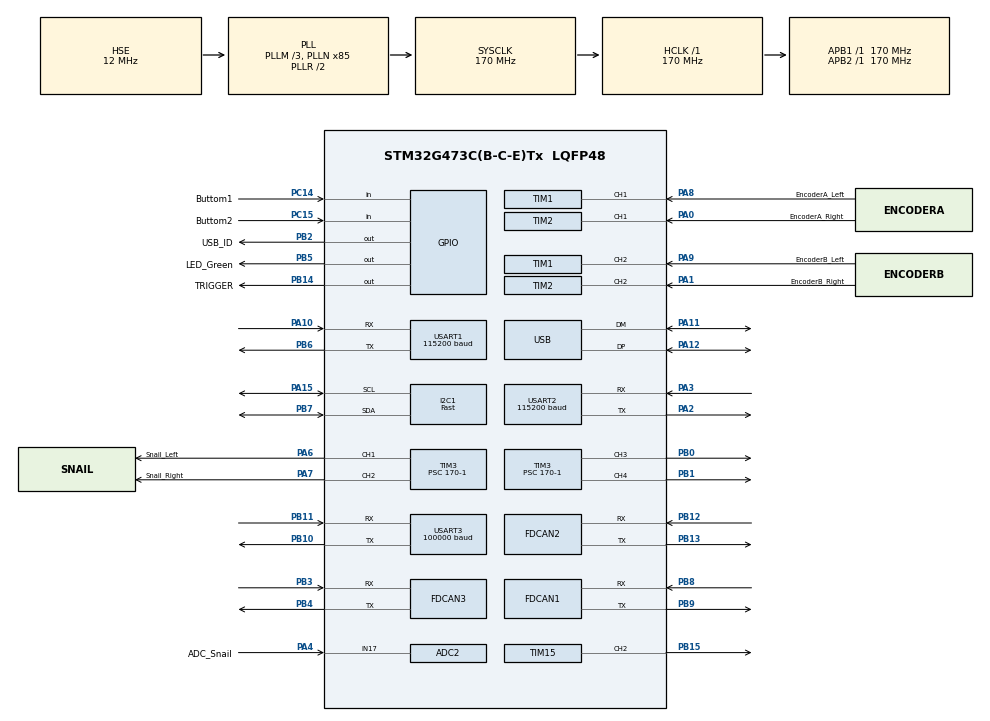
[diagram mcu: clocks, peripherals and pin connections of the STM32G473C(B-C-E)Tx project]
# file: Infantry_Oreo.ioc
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ADC2.Channel-2\#ChannelRegularConversion=ADC_CHANNEL_17
ADC2.ContinuousConvMode=ENABLE
ADC2.DMAContinuousRequests=ENABLE
ADC2.EOCSelection=ADC_EOC_SEQ_CONV
ADC2.NbrOfConversion=1
ADC2.NbrOfConversionFlag=1
ADC2.OffsetNumber-2\#ChannelRegularConversion=ADC_OFFSET_NONE
ADC2.OversamplingMode=ENABLE
ADC2.Rank-2\#ChannelRegularConversion=1
ADC2.Ratio=ADC_OVERSAMPLING_RATIO_256
ADC2.RightBitShift=ADC_RIGHTBITSHIFT_4
ADC2.SamplingTime-2\#ChannelRegularConversion=ADC_SAMPLETIME_6CYCLES_5
Dma.ADC2.3.Direction=DMA_PERIPH_TO_MEMORY
Dma.ADC2.3.EventEnable=DISABLE
Dma.ADC2.3.Instance=DMA1_Channel2
Dma.ADC2.3.MemDataAlignment=DMA_MDATAALIGN_WORD
Dma.ADC2.3.MemInc=DMA_MINC_ENABLE
Dma.ADC2.3.Mode=DMA_CIRCULAR
Dma.ADC2.3.PeriphDataAlignment=DMA_PDATAALIGN_WORD
Dma.ADC2.3.PeriphInc=DMA_PINC_DISABLE
Dma.ADC2.3.Polarity=HAL_DMAMUX_REQ_GEN_RISING
Dma.ADC2.3.Priority=DMA_PRIORITY_LOW
Dma.ADC2.3.RequestNumber=1
Dma.ADC2.3.SignalID=NONE
Dma.ADC2.3.SyncEnable=DISABLE
Dma.ADC2.3.SyncPolarity=HAL_DMAMUX_SYNC_NO_EVENT
Dma.ADC2.3.SyncRequestNumber=1
Dma.ADC2.3.SyncSignalID=NONE
Dma.Request0=USART2_RX
Dma.Request1=USART1_RX
Dma.Request2=USART3_RX
Dma.Request3=ADC2
Dma.USART1_RX.1.Direction=DMA_PERIPH_TO_MEMORY
Dma.USART1_RX.1.EventEnable=DISABLE
Dma.USART1_RX.1.Instance=DMA1_Channel4
Dma.USART1_RX.1.MemDataAlignment=DMA_MDATAALIGN_BYTE
Dma.USART1_RX.1.MemInc=DMA_MINC_ENABLE
Dma.USART1_RX.1.Mode=DMA_CIRCULAR
Dma.USART1_RX.1.PeriphDataAlignment=DMA_PDATAALIGN_BYTE
Dma.USART1_RX.1.PeriphInc=DMA_PINC_DISABLE
Dma.USART1_RX.1.Polarity=HAL_DMAMUX_REQ_GEN_RISING
Dma.USART1_RX.1.Priority=DMA_PRIORITY_LOW
Dma.USART1_RX.1.RequestNumber=1
Dma.USART1_RX.1.SignalID=NONE
Dma.USART1_RX.1.SyncEnable=DISABLE
Dma.USART1_RX.1.SyncPolarity=HAL_DMAMUX_SYNC_NO_EVENT
Dma.USART1_RX.1.SyncRequestNumber=1
Dma.USART1_RX.1.SyncSignalID=NONE
Dma.USART2_RX.0.Direction=DMA_PERIPH_TO_MEMORY
Dma.USART2_RX.0.EventEnable=DISABLE
Dma.USART2_RX.0.Instance=DMA1_Channel3
Dma.USART2_RX.0.MemDataAlignment=DMA_MDATAALIGN_BYTE
Dma.USART2_RX.0.MemInc=DMA_MINC_ENABLE
Dma.USART2_RX.0.Mode=DMA_CIRCULAR
Dma.USART2_RX.0.PeriphDataAlignment=DMA_PDATAALIGN_BYTE
Dma.USART2_RX.0.PeriphInc=DMA_PINC_DISABLE
Dma.USART2_RX.0.Polarity=HAL_DMAMUX_REQ_GEN_RISING
Dma.USART2_RX.0.Priority=DMA_PRIORITY_LOW
Dma.USART2_RX.0.RequestNumber=1
Dma.USART2_RX.0.SignalID=NONE
Dma.USART2_RX.0.SyncEnable=DISABLE
Dma.USART2_RX.0.SyncPolarity=HAL_DMAMUX_SYNC_NO_EVENT
Dma.USART2_RX.0.SyncRequestNumber=1
Dma.USART2_RX.0.SyncSignalID=NONE
Dma.USART3_RX.2.Direction=DMA_PERIPH_TO_MEMORY
Dma.USART3_RX.2.EventEnable=DISABLE
Dma.USART3_RX.2.Instance=DMA1_Channel1
Dma.USART3_RX.2.MemDataAlignment=DMA_MDATAALIGN_BYTE
Dma.USART3_RX.2.MemInc=DMA_MINC_ENABLE
Dma.USART3_RX.2.Mode=DMA_CIRCULAR
Dma.USART3_RX.2.PeriphDataAlignment=DMA_PDATAALIGN_BYTE
Dma.USART3_RX.2.PeriphInc=DMA_PINC_DISABLE
Dma.USART3_RX.2.Polarity=HAL_DMAMUX_REQ_GEN_RISING
Dma.USART3_RX.2.Priority=DMA_PRIORITY_LOW
Dma.USART3_RX.2.RequestNumber=1
Dma.USART3_RX.2.SignalID=NONE
Dma.USART3_RX.2.SyncEnable=DISABLE
Dma.USART3_RX.2.SyncPolarity=HAL_DMAMUX_SYNC_NO_EVENT
Dma.USART3_RX.2.SyncRequestNumber=1
Dma.USART3_RX.2.SyncSignalID=NONE
FDCAN1.AutoRetransmission=DISABLE
FDCAN1.DataPrescaler=2
FDCAN1.DataTimeSeg1=10
FDCAN1.DataTimeSeg2=6
FDCAN1.ExtFiltersNbr=8
FDCAN1.FrameFormat=FDCAN_FRAME_FD_BRS
FDCAN1.Mode=FDCAN_MODE_NORMAL
FDCAN1.NominalPrescaler=17
FDCAN1.NominalTimeSeg1=6
FDCAN1.NominalTimeSeg2=3
FDCAN1.ProtocolException=DISABLE
FDCAN1.StdFiltersNbr=8
FDCAN1.TransmitPause=DISABLE
FDCAN2.AutoRetransmission=DISABLE
FDCAN2.DataPrescaler=2
FDCAN2.DataTimeSeg1=10
FDCAN2.DataTimeSeg2=6
FDCAN2.ExtFiltersNbr=8
FDCAN2.FrameFormat=FDCAN_FRAME_FD_BRS
FDCAN2.Mode=FDCAN_MODE_NORMAL
FDCAN2.NominalPrescaler=17
FDCAN2.NominalTimeSeg1=6
FDCAN2.NominalTimeSeg2=3
FDCAN2.ProtocolException=DISABLE
FDCAN2.StdFiltersNbr=8
FDCAN2.TransmitPause=DISABLE
FDCAN3.AutoRetransmission=DISABLE
FDCAN3.DataPrescaler=2
FDCAN3.DataTimeSeg1=10
FDCAN3.DataTimeSeg2=6
FDCAN3.ExtFiltersNbr=8
FDCAN3.FrameFormat=FDCAN_FRAME_FD_BRS
FDCAN3.Mode=FDCAN_MODE_NORMAL
FDCAN3.NominalPrescaler=17
FDCAN3.NominalTimeSeg1=6
FDCAN3.NominalTimeSeg2=3
FDCAN3.ProtocolException=DISABLE
FDCAN3.StdFiltersNbr=8
FDCAN3.TransmitPause=DISABLE
FREERTOS.INCLUDE_eTaskGetState=1
FREERTOS.INCLUDE_pcTaskGetTaskName=1
FREERTOS.INCLUDE_uxTaskGetStackHighWaterMark=1
FREERTOS.INCLUDE_uxTaskGetStackHighWaterMark2=1
FREERTOS.INCLUDE_vTaskCleanUpResources=1
FREERTOS.INCLUDE_vTaskDelayUntil=1
FREERTOS.INCLUDE_xQueueGetMutexHolder=1
FREERTOS.INCLUDE_xSemaphoreGetMutexHolder=1
FREERTOS.INCLUDE_xTaskAbortDelay=1
FREERTOS.INCLUDE_xTaskGetCurrentTaskHandle=1
FREERTOS.INCLUDE_xTaskGetHandle=1
FREERTOS.MEMORY_ALLOCATION=2
FREERTOS.Queues01=Key_Queue,16,uint16_t,0,Dynamic,NULL,NULL
FREERTOS.Tasks01=defaultTask,0,128,StartDefaultTask,As weak,NULL,Dynamic,NULL,NULL;Gimbal,2,128,Gimbal_Task,As weak,NULL,Dynamic,NULL,NULL;BusComm,3,128,BusComm_Task,As weak,NULL,Dynamic,NULL,NULL;Chassis,2,128,Chassis_Task,As weak,NULL,Dynamic,NULL,NULL;Shoot,2,128,Shoot_Task,As weak,NULL,Dynamic,NULL,NULL;MiniPC,0,128,MiniPC_Task,As weak,NULL,Dynamic,NULL,NULL;Referee,2,128,Referee_Task,As weak,NULL,Dynamic,NULL,NULL;WatchDog,0,128,WatchDog_Task,As weak,NULL,Dynamic,NULL,NULL;Client,0,128,Client_Task,As weak,NULL,Dynamic,NULL,NULL;Ins,0,128,Ins_Task,As weak,NULL,Dynamic,NULL,NULL;Init,3,128,Init_Task,As weak,NULL,Dynamic,NULL,NULL;SuperCap,2,128,SuperCap_Task,As weak,NULL,Dynamic,NULL,NULL
FREERTOS.configENABLE_FPU=1
FREERTOS.configTOTAL_HEAP_SIZE=15360
I2C1.I2C_Speed_Mode=I2C_Fast
I2C1.Timing=0x10802D9B
Mcu.Family=STM32G4
Mcu.Name=STM32G473C(B-C-E)Tx
Mcu.Package=LQFP48
NVIC.ADC1_2_IRQn=true\:5\:0\:false\:false\:true\:true\:true\:true\:true
NVIC.DMA1_Channel1_IRQn=true\:5\:0\:false\:false\:true\:true\:false\:true\:true
NVIC.DMA1_Channel2_IRQn=true\:5\:0\:false\:false\:true\:true\:false\:true\:true
NVIC.DMA1_Channel3_IRQn=true\:5\:0\:false\:false\:true\:true\:false\:true\:true
NVIC.DMA1_Channel4_IRQn=true\:5\:0\:false\:false\:true\:true\:false\:true\:true
NVIC.FDCAN1_IT0_IRQn=true\:5\:0\:false\:false\:true\:true\:true\:true\:true
NVIC.FDCAN2_IT0_IRQn=true\:5\:0\:false\:false\:true\:true\:true\:true\:true
NVIC.FDCAN3_IT0_IRQn=true\:5\:0\:false\:false\:true\:true\:true\:true\:true
NVIC.PriorityGroup=NVIC_PRIORITYGROUP_4
NVIC.TIM20_UP_IRQn=true\:15\:0\:false\:false\:true\:false\:false\:true\:true
NVIC.TimeBase=TIM20_UP_IRQn
NVIC.TimeBaseIP=TIM20
NVIC.USART1_IRQn=true\:5\:0\:false\:false\:true\:true\:true\:true\:true
NVIC.USART2_IRQn=true\:5\:0\:false\:false\:true\:true\:true\:true\:true
NVIC.USART3_IRQn=true\:5\:0\:false\:false\:true\:true\:true\:true\:true
NVIC.USB_LP_IRQn=true\:5\:0\:false\:false\:true\:true\:false\:true\:true
PA0.GPIO_Label=EncoderA_Right
PA0.Signal=S_TIM2_CH1
PA1.GPIO_Label=EncoderB_Right
PA1.Signal=S_TIM2_CH2
PA10.Mode=Asynchronous
PA10.Signal=USART1_RX
PA11.Mode=Device
PA11.Signal=USB_DM
PA12.Mode=Device
PA12.Signal=USB_DP
PA13.Mode=Serial_Wire
PA13.Signal=SYS_JTMS-SWDIO
PA14.Mode=Serial_Wire
PA14.Signal=SYS_JTCK-SWCLK
PA15.Mode=I2C
PA15.Signal=I2C1_SCL
PA2.Mode=Asynchronous
PA2.Signal=USART2_TX
PA3.Mode=Asynchronous
PA3.Signal=USART2_RX
PA4.GPIO_Label=ADC_Snail
PA4.Mode=IN17-Single-Ended
PA4.Signal=ADC2_IN17
PA6.GPIO_Label=Snail_Left
PA6.Signal=S_TIM3_CH1
PA7.GPIO_Label=Snail_Right
PA7.Signal=S_TIM3_CH2
PA8.GPIO_Label=EncoderA_Left
PA8.Signal=S_TIM1_CH1
PA9.GPIO_Label=EncoderB_Left
PA9.Signal=S_TIM1_CH2
PB0.Signal=S_TIM3_CH3
PB1.Signal=S_TIM3_CH4
PB10.Mode=Asynchronous
PB10.Signal=USART3_TX
PB11.Mode=Asynchronous
PB11.Signal=USART3_RX
PB12.Mode=FDCAN_Activate
PB12.Signal=FDCAN2_RX
PB13.Mode=FDCAN_Activate
PB13.Signal=FDCAN2_TX
PB14.GPIO_Label=TRIGGER
PB14.GPIO_Speed=GPIO_SPEED_FREQ_MEDIUM
PB14.Signal=GPIO_Output
PB15.Signal=S_TIM15_CH2
PB2.GPIO_Label=USB_ID
PB2.Signal=GPIO_Output
PB3.Mode=FDCAN_Activate
PB3.Signal=FDCAN3_RX
PB4.Mode=FDCAN_Activate
PB4.Signal=FDCAN3_TX
PB5.GPIO_Label=LED_Green
PB5.Signal=GPIO_Output
PB6.Mode=Asynchronous
PB6.Signal=USART1_TX
PB7.Mode=I2C
PB7.Signal=I2C1_SDA
PB8-BOOT0.Mode=FDCAN_Activate
PB8-BOOT0.Signal=FDCAN1_RX
PB9.Mode=FDCAN_Activate
PB9.Signal=FDCAN1_TX
PC14-OSC32_IN.GPIO_Label=Buttom1
PC14-OSC32_IN.Signal=GPIO_Input
PC15-OSC32_OUT.GPIO_Label=Buttom2
PC15-OSC32_OUT.Signal=GPIO_Input
PF0-OSC_IN.Mode=HSE-External-Oscillator
PF0-OSC_IN.Signal=RCC_OSC_IN
PF1-OSC_OUT.Mode=HSE-External-Oscillator
PF1-OSC_OUT.Signal=RCC_OSC_OUT
ProjectManager.HeapSize=0x1000
ProjectManager.StackSize=0x8000
ProjectManager.TargetToolchain=MDK-ARM V5.32
RCC.ADC12Freq_Value=170000000
RCC.ADC345Freq_Value=170000000
RCC.AHBFreq_Value=170000000
RCC.APB1Freq_Value=170000000
RCC.APB1TimFreq_Value=170000000
RCC.APB2Freq_Value=170000000
RCC.APB2TimFreq_Value=170000000
RCC.CK48CLockSelection=RCC_USBCLKSOURCE_HSI48
RCC.CortexFreq_Value=170000000
RCC.EXTERNAL_CLOCK_VALUE=12288000
RCC.HCLKFreq_Value=170000000
RCC.HSE_VALUE=12000000
RCC.HSI48_VALUE=48000000
RCC.HSI_VALUE=16000000
RCC.LSE_VALUE=32768
RCC.PLLM=RCC_PLLM_DIV3
RCC.PLLN=85
RCC.PLLQ=RCC_PLLQ_DIV4
RCC.PLLSourceVirtual=RCC_PLLSOURCE_HSE
RCC.SYSCLKFreq_VALUE=170000000
RCC.SYSCLKSource=RCC_SYSCLKSOURCE_PLLCLK
RCC.USBFreq_Value=48000000
RCC.VCOOutputFreq_Value=340000000
SH.S_TIM15_CH2.0=TIM15_CH2,PWM Generation2 CH2
SH.S_TIM1_CH1.0=TIM1_CH1,Encoder_Interface
SH.S_TIM1_CH2.0=TIM1_CH2,Encoder_Interface
SH.S_TIM2_CH1.0=TIM2_CH1,Encoder_Interface
SH.S_TIM2_CH2.0=TIM2_CH2,Encoder_Interface
SH.S_TIM3_CH1.0=TIM3_CH1,PWM Generation1 CH1
SH.S_TIM3_CH2.0=TIM3_CH2,PWM Generation2 CH2
SH.S_TIM3_CH3.0=TIM3_CH3,PWM Generation3 CH3
SH.S_TIM3_CH4.0=TIM3_CH4,PWM Generation4 CH4
SYS.VoltageScaling=SYSCFG_VREFBUF_VOLTAGE_SCALE2
TIM1.AutoReloadPreload=TIM_AUTORELOAD_PRELOAD_DISABLE
TIM1.EncoderMode=TIM_ENCODERMODE_TI12
TIM1.IC1Filter=5
TIM1.IC2Filter=5
TIM15.Channel-PWM\ Generation2\ CH2=TIM_CHANNEL_2
TIM16.PeriodNoDither=65535
TIM16.Prescaler=0
TIM2.EncoderMode=TIM_ENCODERMODE_TI12
TIM2.IC1Filter=5
TIM2.IC2Filter=5
TIM2.PeriodNoDither=65535
TIM3.Channel-PWM\ Generation1\ CH1=TIM_CHANNEL_1
TIM3.Channel-PWM\ Generation2\ CH2=TIM_CHANNEL_2
TIM3.Channel-PWM\ Generation3\ CH3=TIM_CHANNEL_3
TIM3.Channel-PWM\ Generation4\ CH4=TIM_CHANNEL_4
TIM3.PeriodNoDither=2000-1
TIM3.Prescaler=170-1
USART1.BaudRate=115200
USART1.Parity=PARITY_NONE
USART1.RxPinLevelInvertParam=ADVFEATURE_RXINV_DISABLE
USART1.VirtualMode-Asynchronous=VM_ASYNC
USART1.WordLength=WORDLENGTH_8B
USART2.BaudRate=115200
USART2.Parity=PARITY_NONE
USART2.VirtualMode-Asynchronous=VM_ASYNC
USART2.WordLength=WORDLENGTH_8B
USART3.BaudRate=100000
USART3.Parity=PARITY_EVEN
USART3.RxPinLevelInvertParam=ADVFEATURE_RXINV_ENABLE
USART3.VirtualMode-Asynchronous=VM_ASYNC
USART3.WordLength=WORDLENGTH_9B
USB_DEVICE.CLASS_NAME_FS=CDC
USB_DEVICE.VirtualMode=Cdc
USB_DEVICE.VirtualModeFS=Cdc_FS
VP_FREERTOS_VS_CMSIS_V1.Mode=CMSIS_V1
VP_SYS_VS_DBSignals.Mode=DisableDeadBatterySignals
VP_SYS_VS_tim20.Mode=TIM20
VP_TIM15_VS_ClockSourceINT.Mode=Internal
VP_TIM16_VS_ClockSourceINT.Mode=Enable_Timer
VP_TIM17_VS_ClockSourceINT.Mode=Enable_Timer
VP_TIM3_VS_ClockSourceINT.Mode=Internal
VP_TIM4_VS_ClockSourceINT.Mode=Internal
VP_TIM5_VS_ClockSourceINT.Mode=Internal
VP_TIM6_VS_ClockSourceINT.Mode=Enable_Timer
VP_TIM7_VS_ClockSourceINT.Mode=Enable_Timer
VP_TIM8_VS_ClockSourceINT.Mode=Internal
VP_USB_DEVICE_VS_USB_DEVICE_CDC_FS.Mode=CDC_FS
VREF+.Mode=InternalMode
VREF+.Signal=VREFBUF_OUT
board=custom

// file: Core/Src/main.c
/* USER CODE BEGIN Header */
/**
 ******************************************************************************
 * @file           : main.c
 * @brief          : Main program body
 ******************************************************************************
 * @attention
 *
 * Copyright (c) 2022 STMicroelectronics.
 * All rights reserved.
 *
 * This software is licensed under terms that can be found in the LICENSE file
 * in the root directory of this software component.
 * If no LICENSE file comes with this software, it is provided AS-IS.
 *
 ******************************************************************************
 */
/* USER CODE END Header */
#include "main.h"
#include "cmsis_os.h"
#include "adc.h"
#include "dma.h"
#include "fdcan.h"
#include "i2c.h"
#include "tim.h"
#include "usart.h"
#include "usb_device.h"
#include "gpio.h"

void SystemClock_Config(void);
void MX_FREERTOS_Init(void);

int main(void){

  /* MCU Configuration--------------------------------------------------------*/

  /* Reset of all peripherals, Initializes the Flash interface and the Systick. */
  HAL_Init();

  /* Configure the system clock */
  SystemClock_Config();

  /* USER CODE BEGIN SysInit */
    // DMA and usart;
    MX_DMA_Init();
  /* USER CODE END SysInit */

  /* Initialize all configured peripherals */
  MX_GPIO_Init();
  MX_FDCAN1_Init();
  MX_FDCAN2_Init();
  MX_FDCAN3_Init();
  MX_I2C1_Init();
  MX_TIM1_Init();
  MX_TIM2_Init();
  MX_TIM15_Init();
  MX_USART1_UART_Init();
  MX_USART2_UART_Init();
  MX_DMA_Init();
  MX_USB_Device_Init();
  MX_USART3_UART_Init();
  MX_TIM3_Init();
  MX_TIM5_Init();
  MX_ADC2_Init();
  MX_TIM16_Init();
  MX_TIM4_Init();
  MX_TIM6_Init();
  MX_TIM7_Init();
  MX_TIM8_Init();
  MX_TIM17_Init();

  /* Call init function for freertos objects (in freertos.c) */
  MX_FREERTOS_Init();

  /* Start scheduler */
  osKernelStart();

  /* We should never get here as control is now taken by the scheduler */
  /* Infinite loop */
    while (1) {

    }
}

void SystemClock_Config(void)
{
  RCC_OscInitTypeDef RCC_OscInitStruct = {0};
  RCC_ClkInitTypeDef RCC_ClkInitStruct = {0};

  /** Configure the main internal regulator output voltage
  */
  HAL_PWREx_ControlVoltageScaling(PWR_REGULATOR_VOLTAGE_SCALE1_BOOST);

  /** Initializes the RCC Oscillators according to the specified parameters
  * in the RCC_OscInitTypeDef structure.
  */
  RCC_OscInitStruct.OscillatorType = RCC_OSCILLATORTYPE_HSI48|RCC_OSCILLATORTYPE_HSE;
  RCC_OscInitStruct.HSEState = RCC_HSE_ON;
  RCC_OscInitStruct.HSI48State = RCC_HSI48_ON;
  RCC_OscInitStruct.PLL.PLLState = RCC_PLL_ON;
  RCC_OscInitStruct.PLL.PLLSource = RCC_PLLSOURCE_HSE;
  RCC_OscInitStruct.PLL.PLLM = RCC_PLLM_DIV3;
  RCC_OscInitStruct.PLL.PLLN = 85;
  RCC_OscInitStruct.PLL.PLLP = RCC_PLLP_DIV2;
  RCC_OscInitStruct.PLL.PLLQ = RCC_PLLQ_DIV4;
  RCC_OscInitStruct.PLL.PLLR = RCC_PLLR_DIV2;
  if (HAL_RCC_OscConfig(&RCC_OscInitStruct) != HAL_OK)
  {
    Error_Handler();
  }

  /** Initializes the CPU, AHB and APB buses clocks
  */
  RCC_ClkInitStruct.ClockType = RCC_CLOCKTYPE_HCLK|RCC_CLOCKTYPE_SYSCLK
                              |RCC_CLOCKTYPE_PCLK1|RCC_CLOCKTYPE_PCLK2;
  RCC_ClkInitStruct.SYSCLKSource = RCC_SYSCLKSOURCE_PLLCLK;
  RCC_ClkInitStruct.AHBCLKDivider = RCC_SYSCLK_DIV1;
  RCC_ClkInitStruct.APB1CLKDivider = RCC_HCLK_DIV1;
  RCC_ClkInitStruct.APB2CLKDivider = RCC_HCLK_DIV1;

  if (HAL_RCC_ClockConfig(&RCC_ClkInitStruct, FLASH_LATENCY_4) != HAL_OK)
  {
    Error_Handler();
  }
}

void HAL_TIM_PeriodElapsedCallback(TIM_HandleTypeDef *htim)
{
  if (htim->Instance == TIM20) {
    HAL_IncTick();
  }
}

void Error_Handler(void)
{
    __disable_irq();
    while (1) {
    }
}

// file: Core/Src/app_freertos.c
/* USER CODE BEGIN Header */
/**
 ******************************************************************************
 * File Name          : app_freertos.c
 * Description        : Code for freertos applications
 ******************************************************************************
 * @attention
 *
 * Copyright (c) 2022 STMicroelectronics.
 * All rights reserved.
 *
 * This software is licensed under terms that can be found in the LICENSE file
 * in the root directory of this software component.
 * If no LICENSE file comes with this software, it is provided AS-IS.
 *
 ******************************************************************************
 */
/* USER CODE END Header */

#include "FreeRTOS.h"
#include "task.h"
#include "main.h"
#include "cmsis_os.h"

osThreadId defaultTaskHandle;
osThreadId GimbalHandle;
osThreadId BusCommHandle;
osThreadId ChassisHandle;
osThreadId ShootHandle;
osThreadId MiniPCHandle;
osThreadId RefereeHandle;
osThreadId WatchDogHandle;
osThreadId ClientHandle;
osThreadId InsHandle;
osThreadId InitHandle;
osThreadId SuperCapHandle;
osMessageQId Key_QueueHandle;

void StartDefaultTask(void const * argument);
void Gimbal_Task(void const * argument);
void BusComm_Task(void const * argument);
void Chassis_Task(void const * argument);
void Shoot_Task(void const * argument);
void MiniPC_Task(void const * argument);
void Referee_Task(void const * argument);
void WatchDog_Task(void const * argument);
void Client_Task(void const * argument);
void Ins_Task(void const * argument);
void Init_Task(void const * argument);
void SuperCap_Task(void const * argument);

void MX_FREERTOS_Init(void); /* (MISRA C 2004 rule 8.1) */

/* GetIdleTaskMemory prototype (linked to static allocation support) */
void vApplicationGetIdleTaskMemory( StaticTask_t **ppxIdleTaskTCBBuffer, StackType_t **ppxIdleTaskStackBuffer, uint32_t *pulIdleTaskStackSize );

/* USER CODE BEGIN GET_IDLE_TASK_MEMORY */
static StaticTask_t xIdleTaskTCBBuffer;
static StackType_t xIdleStack[configMINIMAL_STACK_SIZE];

void vApplicationGetIdleTaskMemory(StaticTask_t** ppxIdleTaskTCBBuffer, StackType_t** ppxIdleTaskStackBuffer, uint32_t* pulIdleTaskStackSize) {
    *ppxIdleTaskTCBBuffer = &xIdleTaskTCBBuffer;
    *ppxIdleTaskStackBuffer = &xIdleStack[0];
    *pulIdleTaskStackSize = configMINIMAL_STACK_SIZE;
    /* place for user code */
}
/* USER CODE END GET_IDLE_TASK_MEMORY */

void MX_FREERTOS_Init(void) {

  /* Create the queue(s) */
  /* definition and creation of Key_Queue */
  osMessageQDef(Key_Queue, 16, uint16_t);
  Key_QueueHandle = osMessageCreate(osMessageQ(Key_Queue), NULL);

  /* Create the thread(s) */
  /* definition and creation of defaultTask */
  osThreadDef(defaultTask, StartDefaultTask, osPriorityNormal, 0, 128);
  defaultTaskHandle = osThreadCreate(osThread(defaultTask), NULL);

  /* definition and creation of Gimbal */
  osThreadDef(Gimbal, Gimbal_Task, osPriorityHigh, 0, 128);
  GimbalHandle = osThreadCreate(osThread(Gimbal), NULL);

  /* definition and creation of BusComm */
  osThreadDef(BusComm, BusComm_Task, osPriorityRealtime, 0, 128);
  BusCommHandle = osThreadCreate(osThread(BusComm), NULL);

  /* definition and creation of Chassis */
  osThreadDef(Chassis, Chassis_Task, osPriorityHigh, 0, 128);
  ChassisHandle = osThreadCreate(osThread(Chassis), NULL);

  /* definition and creation of Shoot */
  osThreadDef(Shoot, Shoot_Task, osPriorityHigh, 0, 128);
  ShootHandle = osThreadCreate(osThread(Shoot), NULL);

  /* definition and creation of MiniPC */
  osThreadDef(MiniPC, MiniPC_Task, osPriorityNormal, 0, 128);
  MiniPCHandle = osThreadCreate(osThread(MiniPC), NULL);

  /* definition and creation of Referee */
  osThreadDef(Referee, Referee_Task, osPriorityHigh, 0, 128);
  RefereeHandle = osThreadCreate(osThread(Referee), NULL);

  /* definition and creation of WatchDog */
  osThreadDef(WatchDog, WatchDog_Task, osPriorityNormal, 0, 128);
  WatchDogHandle = osThreadCreate(osThread(WatchDog), NULL);

  /* definition and creation of Client */
  osThreadDef(Client, Client_Task, osPriorityNormal, 0, 128);
  ClientHandle = osThreadCreate(osThread(Client), NULL);

  /* definition and creation of Ins */
  osThreadDef(Ins, Ins_Task, osPriorityNormal, 0, 128);
  InsHandle = osThreadCreate(osThread(Ins), NULL);

  /* definition and creation of Init */
  osThreadDef(Init, Init_Task, osPriorityRealtime, 0, 128);
  InitHandle = osThreadCreate(osThread(Init), NULL);

  /* definition and creation of SuperCap */
  osThreadDef(SuperCap, SuperCap_Task, osPriorityHigh, 0, 128);
  SuperCapHandle = osThreadCreate(osThread(SuperCap), NULL);

}

__weak void StartDefaultTask(void const * argument)
{
    for (;;) {
        osDelay(1);
    }
}

__weak void Gimbal_Task(void const * argument)
{
    for (;;) {
        osDelay(1);
    }
}

__weak void BusComm_Task(void const * argument)
{
    for (;;) {
        osDelay(1);
    }
}

__weak void Chassis_Task(void const * argument)
{
    for (;;) {
        osDelay(1);
    }
}

__weak void Shoot_Task(void const * argument)
{
    for (;;) {
        osDelay(1);
    }
}

__weak void MiniPC_Task(void const * argument)
{
    for (;;) {
        osDelay(1);
    }
}

__weak void Referee_Task(void const * argument)
{
    for (;;) {
        osDelay(1);
    }
}

__weak void WatchDog_Task(void const * argument)
{
    for (;;) {
        osDelay(1);
    }
}

__weak void Client_Task(void const * argument)
{
    for (;;) {
        osDelay(1);
    }
}

__weak void Ins_Task(void const * argument)
{
    for (;;) {
        osDelay(1);
    }
}

__weak void Init_Task(void const * argument)
{
    for (;;) {
        osDelay(1);
    }
}

__weak void SuperCap_Task(void const * argument)
{
    for (;;) {
        osDelay(1);
    }
}
